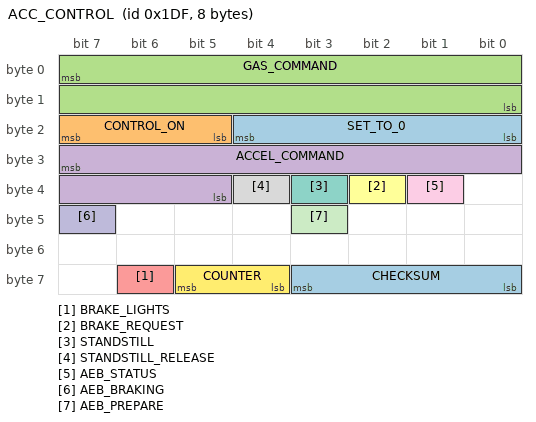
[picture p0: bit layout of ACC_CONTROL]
BO_ 479 ACC_CONTROL: 8 EON
 SG_ SET_TO_0 : 20|5@0+ (1,0) [0|1] "" XXX
 SG_ CONTROL_ON : 23|3@0+ (1,0) [0|5] "" XXX
 SG_ GAS_COMMAND : 7|16@0- (1,0) [0|0] "" XXX
 SG_ ACCEL_COMMAND : 31|11@0- (0.01,0) [0|0] "m/s2" XXX
 SG_ BRAKE_LIGHTS : 62|1@0+ (1,0) [0|1] "" XXX
 SG_ BRAKE_REQUEST : 34|1@0+ (1,0) [0|1] "" XXX
 SG_ STANDSTILL : 35|1@0+ (1,0) [0|1] "" XXX
 SG_ STANDSTILL_RELEASE : 36|1@0+ (1,0) [0|1] "" XXX
 SG_ AEB_STATUS : 33|1@0+ (1,0) [0|1] "" XXX
 SG_ AEB_BRAKING : 47|1@0+ (1,0) [0|1] "" XXX
 SG_ AEB_PREPARE : 43|1@0+ (1,0) [0|1] "" XXX
 SG_ COUNTER : 61|2@0+ (1,0) [0|3] "" XXX
 SG_ CHECKSUM : 59|4@0+ (1,0) [0|15] "" XXX

CM_ BO_ 479 "This message is only used on bosch_2018 cars";
CM_ SG_ 479 CONTROL_ON "Set to 5 when car is being controlled";
CM_ SG_ 479 AEB_STATUS "set for the duration of AEB event";
CM_ SG_ 479 AEB_BRAKING "set when braking is commanded during AEB event";
CM_ SG_ 479 AEB_PREPARE "set 1s before AEB";
